# SAMA7G54D2GN4 register map
Vendor: Microchip Technology; Series: SAMA7G5; File version: 0
Registers are 32-bit, read-write, reset 0x0 unless marked. A register's access mark holds for its fields unless they carry their own. Offsets are from the block's base; [hi:lo] are bit positions; 'fields as' and 'values as' point back to an identical list.

## RSTC — Reset Controller
Base 0xE001D000
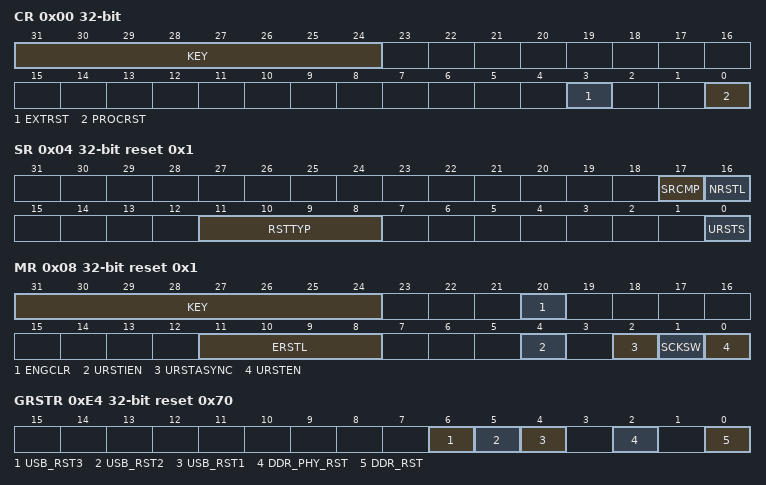
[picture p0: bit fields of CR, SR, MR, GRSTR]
0x00 CR wo — Control Register
  [31:24] KEY — System Reset Key
    165=PASSWD (Writing any other value in this field aborts the write operation.)
  [3] EXTRST — External Reset
    0=No effect; 1=If KEY = 0xA5, asserts the NRST_OUT pin
  [0] PROCRST — Processor Reset
    0=No effect; 1=If KEY = 0xA5, resets the processor and all the embedded peripherals
0x04 SR ro reset 0x1 — Status Register
  [17] SRCMP — Software Reset Command in Progress
    0=No software command is being performed by the RSTC. The RSTC is ready for a software command.; 1=A Software reset command is being performed by the RSTC. The RSTC is busy.
  [16] NRSTL — NRST Pin Level
  [11:8] RSTTYP — Reset Type
    0=GENERAL_RST (First powerup reset); 1=BACKUP_RST (Return from Backup mode); 2=WDT_RST (Watchdog fault occurred); 3=SOFT_RST (Processor reset required by the software); 4=USER_RST (NRST pin detected low); 7=SLCK_XTAL_RST (32.768 kHz crystal failure detection fault occurred)
  [0] URSTS — User Reset Status
    0=No high-to-low edge on NRST happened since the last read of RSTC_SR; 1=At least one high-to-low transition of NRST has been detected since the last read of RSTC_SR
0x08 MR reset 0x1 — Mode Register
  [31:24] KEY — Write Access Password
    165=PASSWD (Writing any other value in this field aborts the write operation. Always reads as 0.)
  [20] ENGCLR — Enable GPBR Clear on Tamper Event
    0=Disables the GPBR immediate clear on tamper detection event; 1=Enables the GPBR immediate clear on tamper detection event
  [11:8] ERSTL — External Reset Length
  [4] URSTIEN — User Reset Interrupt Enable
    0=RSTC_SR.USRTS at '1' has no effect on the RSTC interrupt line; 1=RSTC_SR.USRTS at '1' asserts the RSTC interrupt line if URSTEN = 0
  [2] URSTASYNC — User Reset Asynchronous Control
    0=The NRST input signal is managed synchronously; 1=The NRST input signal is managed asynchronously. Note: this mode cannot be selected if the external bus interface drives an SDR/DDR memory device and another memory on the same bus.
  [1] SCKSW — Slow Clock Switching
    0=The detection of a 32.768 kHz crystal failure has no effect; 1=The detection of a 32.768 kHz crystal failure resets the logic supplied by VDDCORE
  [0] URSTEN — User Reset Enable
    0=The detection of a low level on the NRST pin does not generate a User reset; 1=The detection of a low level on the NRST pin triggers a User reset
0xE4 GRSTR reset 0x70 — Generic Reset Register
  [6] USB_RST3 — USB Reset
    0=POR_DISABLED (POR is disabled.); 1=POR_ENABLED (POR is enabled.)
  [5] USB_RST2 — USB Reset
    values as USB_RST3
  [4] USB_RST1 — USB Reset
    values as USB_RST3
  [2] DDR_PHY_RST — DDR PHY Reset
    0=DDR PHY reset is asserted; 1=DDR PHY reset is de-asserted
  [0] DDR_RST — DDR Reset
    0=DDR Controller reset is asserted; 1=DDR Controller reset is de-asserted

## RTT — Real-time Timer
Base 0xE001D020
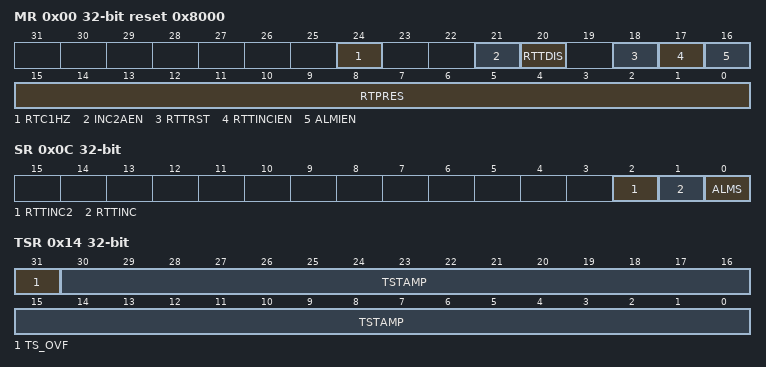
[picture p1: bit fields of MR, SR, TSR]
0x00 MR reset 0x8000 — Mode Register
  [24] RTC1HZ — Real-Time Clock 1Hz Clock Selection
    0=The RTT 32-bit counter is driven by the 16-bit prescaler roll-over events; 1=The RTT 32-bit counter is driven by the 1Hz RTC clock
  [21] INC2AEN — RTTINC2 Alarm and Interrupt Enable
    0=The RTTINC2 flag is not a source of the RTT alarm signal nor a source of interrupt; 1=The RTTINC2 flag is a source of the RTT alarm signal and a source of interrupt
  [20] RTTDIS — Real-Time Timer Disable
    0=The Real-Time Timer is enabled; 1=The Real-Time Timer is disabled (no dynamic power consumption)
  [18] RTTRST — Real-Time Timer Restart
    0=No effect; 1=Reloads and restarts the clock divider with the new programmed value. This also resets the 32-bit counter.
  [17] RTTINCIEN — Real-Time Timer Increment Interrupt Enable
    0=The RTT_SR.RTTINC bit has no effect on interrupt; 1=The RTT_SR.RTTINC bit asserts interrupt
  [16] ALMIEN — Alarm Interrupt Enable
    0=The RTT_SR.ALMS bit has no effect on interrupt; 1=The RTT_SR.ALMS bit asserts interrupt
  [15:0] RTPRES — Real-Time Timer Prescaler Value
0x04 AR reset 0xFFFFFFFF — Alarm Register
  [31:0] ALMV — Alarm Value
0x08 VR ro — Value Register
  [31:0] CRTV — Current Real-time Value
0x0C SR ro — Status Register
  [2] RTTINC2 — Predefined Number of Prescaler Roll-Over Status (cleared on read)
    0=SELINC2=0 or the number of prescaler roll-overs programmed through the SELINC2 field in RTT_MODR has not been reached since the last read of the RTT_SR; 1=The number of prescaler roll-overs programmed through the SELINC2 field has been reached since the last read of the RTT_SR
  [1] RTTINC — Prescaler Roll-over Status (cleared on read)
    0=No prescaler roll-over occurred since the last read of the RTT_SR; 1=Prescaler roll-over occurred since the last read of the RTT_SR
  [0] ALMS — Real-Time Alarm Status (cleared on read)
    0=The real-time zlarm has not occurred since the last read of RTT_SR; 1=The real-time alarm occurred since the last read of RTT_SR
0x10 MODR — Modulo Selection Register
  [2:0] SELINC2 — Selection of the 32-bit Counter Modulo to generate RTTINC2 Flag
    0=NO_RTTINC2 (The RTTINC2 flag never rises.); 1=MOD64 (The RTTINC2 flag is set when CRTV modulo 64 equals 0.); 2=MOD128 (The RTTINC2 flag is set when CRTV modulo 128 equals 0.); 3=MOD256 (The RTTINC2 flag is set when CRTV modulo 256 equals 0.); 4=MOD512 (The RTTINC2 flag is set when CRTV modulo 512 equals 0.); 5=MOD1024 (The RTTINC2 flag is set when CRTV modulo 1024 equals 0. Example: If RTPRES=32 then RTTINC2 flag rises once per second if the slow clock is 32.768 kHz.); 6=MOD2048 (The RTTINC2 flag is set when CRTV modulo 2048 equals 0.); 7=MOD4096 (The RTTINC2 flag is set when CRTV modulo 4096 equals 0.)
0x14 TSR ro — TimeStamp Register
  [31] TS_OVF — Timestamp Overflow
    0=RTT_ST.RTTINC2 was set but no new event occurred since the last read of RTT_SR; 1=RTT_ST.RTTINC2 was set and a second event occurred. To avoid any overflow, clear RTTINC2 by reading RTT_SR.
  [30:0] TSTAMP — Real-Time Timer Value Timestamp
